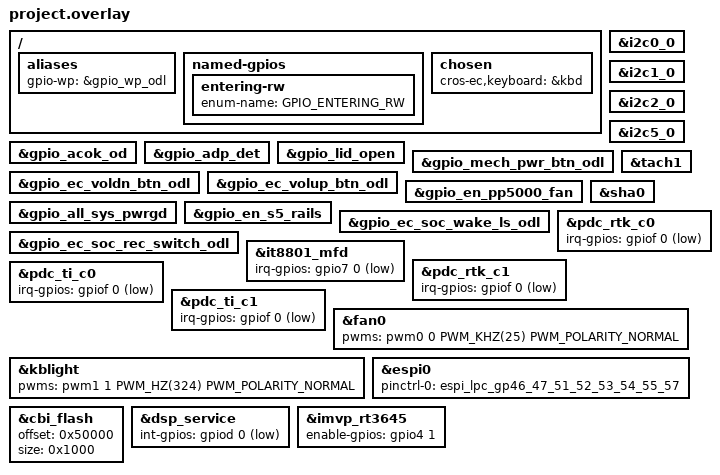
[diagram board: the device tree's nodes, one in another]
/* Copyright 2025 The ChromiumOS Authors
 * Use of this source code is governed by a BSD-style license that can be
 * found in the LICENSE file.
 */

/* ocelot program common DTS includes */

#include <cros/integrated_fwid.dtsi>
#include <cros/cbi_flash.dtsi>

/* ocelotrvp-npcx project DTS includes */
#include "generated.dtsi"
#include "power_signals.dtsi"
#include "psl.dtsi"

/*
 * Map I2C buses to common names
 */

i2c_port_pd1: &i2c0_0 {};
i2c_port_pd2: &i2c1_0 {};
i2c_port_charger: &i2c2_0 {};
i2c_port_ish: &i2c5_0 {};

/*
 * Map GPIOs used for interrupts to common names
 */

gpio_acok: &gpio_acok_od {};
gpio_dc_jack_present: &gpio_adp_det {};
gpio_lid: &gpio_lid_open {};
gpio_pwrbtn: &gpio_mech_pwr_btn_odl {};
gpio_voldn: &gpio_ec_voldn_btn_odl {};
gpio_volup: &gpio_ec_volup_btn_odl {};
gpio_fan_control: &gpio_en_pp5000_fan {};
gpio_all_sys_pwr_good: &gpio_all_sys_pwrgd {};
gpio_temp_sensor_power_good: &gpio_en_s5_rails {};

/* Power sequencing */
gpio_ec_pch_wake_odl: &gpio_ec_soc_wake_ls_odl {};
cse_early_rec_sw: &gpio_ec_soc_rec_switch_odl{};

/* Map tachometers to common names */
tach_fan0: &tach1 {};

#include "../rvp_usba.dtsi"
#include "../rvp_battery.dtsi"
#include "../rvp_i2c.dtsi"
#include "../rvp_interrupts.dtsi"
#include "../rvp_usbc.dtsi"
#include "../rvp_keyboard.dtsi"
#include "../rvp_leds.dtsi"
#include "../rvp_fans.dtsi"
#include "../rvp_temp_sensors.dtsi"
#include "../rvp_ioex_gpio.dtsi"
#include "../rvp_imvp.dtsi"
#include <ite/it8801-common-cfg.dtsi>

&it8801_mfd {
	irq-gpios = <&gpio7 0 GPIO_ACTIVE_LOW>;
};

/* ocelotrvp-npcx overrides follow... */
/ {
	aliases {
		gpio-wp = &gpio_wp_odl;
	};

	named-gpios {
		/* unimplemented GPIOs */
		entering-rw {
			enum-name = "GPIO_ENTERING_RW";
		};
	};

	chosen {
		cros-ec,keyboard = &kbd;
	};
};

&sha0 {
	status = "okay";
};

&pdc_rtk_c0 {
	irq-gpios = <&gpiof 0 GPIO_ACTIVE_LOW>;
};

&pdc_rtk_c1 {
	irq-gpios = <&gpiof 0 GPIO_ACTIVE_LOW>;
};

&pdc_ti_c0 {
	irq-gpios = <&gpiof 0 GPIO_ACTIVE_LOW>;
};

&pdc_ti_c1 {
	irq-gpios = <&gpiof 0 GPIO_ACTIVE_LOW>;
};

&fan0 {
	pwms = <&pwm0 0 PWM_KHZ(25) PWM_POLARITY_NORMAL>;
};

&kblight {
	pwms = <&pwm1 1 PWM_HZ(324) PWM_POLARITY_NORMAL>;
};

&espi0 {
	status = "okay";
	pinctrl-0 = <&espi_lpc_gp46_47_51_52_53_54_55_57>;
	pinctrl-names = "default";
};

/* Required for flashing */
&cbi_flash {
	/*
	 * CBI section size is 0x1000 bytes, the CBI portion lies at the end of
	 * EC_RO section. EC_RO section ends at 0x50000 byte which is the offset
	 */
	offset = <0x50000>;
	size = <0x1000>;
};

&dsp_service {
	int-gpios = <&gpiod 0 (GPIO_ACTIVE_LOW | GPIO_VOLTAGE_1P8)>;
};

&imvp_rt3645 {
	enable-gpios = <&gpio4 1 GPIO_ACTIVE_HIGH>;
};
